VERSION ""

NS_ :

BS_:

BU_: VCU Example_Node

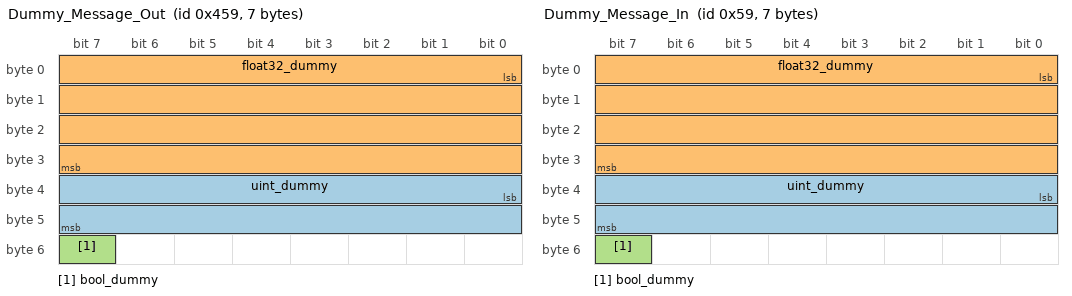
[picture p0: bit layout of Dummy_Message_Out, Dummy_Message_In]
BO_ 1113 Dummy_Message_Out: 7 VCU
 SG_ uint_dummy : 32|16@1+ (1,0) [0|4294967295] ""  VCU
 SG_ float32_dummy : 0|32@1- (0.01,0) [-21474836.48|21474836.47] ""  Example_Node
 SG_ bool_dummy : 55|1@1+ (1,0) [0|1] ""  Example_Node

BO_ 89 Dummy_Message_In: 7 Example_Node
 SG_ uint_dummy : 32|16@1+ (1,0) [0|4294967295] ""  VCU
 SG_ float32_dummy : 0|32@1- (0.01,0) [-21474836.48|21474836.47] ""  VCU
 SG_ bool_dummy : 55|1@1+ (1,0) [0|1] ""  VCU

BA_DEF_  "BusType" STRING ;
BA_DEF_DEF_  "BusType" "";
BA_ "BusType" "CAN";
